AUTOSAR XML (schema 00048)
package /RB/SWCompositions
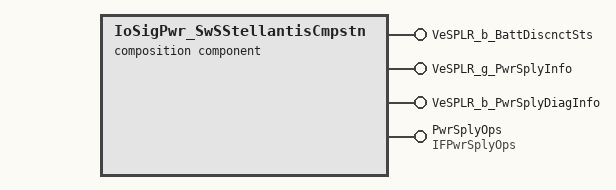
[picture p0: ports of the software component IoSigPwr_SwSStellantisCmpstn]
  composition sw component type IoSigPwr_SwSStellantisCmpstn
    4 x provide port:
      VeSPLR_b_BattDiscnctSts: provided-interface=VeSPLR_b_BattDiscnctSts
      VeSPLR_g_PwrSplyInfo: provided-interface=VeSPLR_g_PwrSplyInfo
      VeSPLR_b_PwrSplyDiagInfo: provided-interface=VeSPLR_b_PwrSplyDiagInfo
      PwrSplyOps: provided-interface=IFPwrSplyOps
    component IoSigPwr_SwSStellantis: type=IoSigPwr_SwSStellantis
    delegate IoSigPwr_SwSStellantis.VeSPLR_b_BattDiscnctSts <-> outer port VeSPLR_b_BattDiscnctSts
    delegate IoSigPwr_SwSStellantis.VeSPLR_g_PwrSplyInfo <-> outer port VeSPLR_g_PwrSplyInfo
    delegate IoSigPwr_SwSStellantis.VeSPLR_b_PwrSplyDiagInfo <-> outer port VeSPLR_b_PwrSplyDiagInfo
    delegate IoSigPwr_SwSStellantis.PwrSplyOps <-> outer port PwrSplyOps
